# MB9BF12xS register map
File version: 1.0
Registers are 32-bit, read-write, reset 0x0 unless marked. A register's access mark holds for its fields unless they carry their own. Offsets are from the block's base; [hi:lo] are bit positions; {n}, {i} and the like mark numbered series; 'fields as' and 'values as' point back to an identical list.

## CRTRIM — peripheral CRTRIM
Base 0x4002E000
0x00 MCR_PSR 8-bit reset 0x1
  [1:0] CSR
0x04 MCR_FTRM 16-bit reset 0x200
  [9:0] TRD
0x08 MCR_TTRM 8-bit reset 0xF
  [4:0] TRT
0x0C MCR_RLR reset 0x1
  [31:0] TRMLCK

## SWWDT — peripheral SWWDT
Base 0x40012000
0x00 WDOGLOAD reset 0xFFFFFFFF
0x04 WDOGVALUE ro reset 0xFFFFFFFF
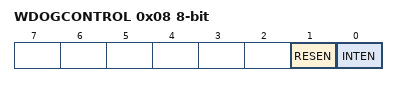
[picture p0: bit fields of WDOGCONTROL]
0x08 WDOGCONTROL 8-bit
  [1] RESEN, [0] INTEN
0x0C WDOGINTCLR reset 0xFFFFFFFF
0x10 WDOGRIS 8-bit ro
  [0] RIS
0xC00 WDOGLOCK

## HWWDT — peripheral HWWDT
Base 0x40011000
0x00 WDG_LDR reset 0xFFFF
0x04 WDG_VLR ro
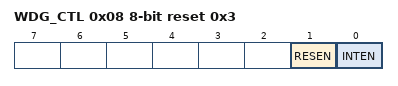
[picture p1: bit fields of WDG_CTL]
0x08 WDG_CTL 8-bit reset 0x3
  [1] RESEN, [0] INTEN
0x0C WDG_ICL 8-bit reset 0xFF (reset mask 0x0)
0x10 WDG_RIS 8-bit ro reset 0xFF (reset mask 0x0)
  [0] RIS
0xC00 WDG_LCK reset 0x1

## DTIM — peripheral DTIM
Base 0x40015000
0x00 TIMER1LOAD (DualTimer1 view)
0x04 TIMER1VALUE ro reset 0xFFFFFFFF
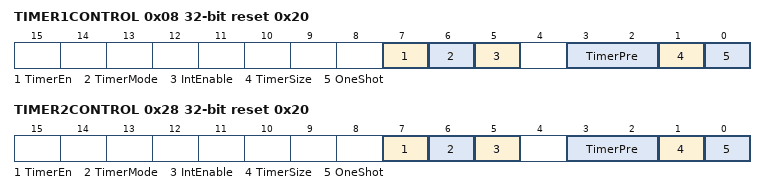
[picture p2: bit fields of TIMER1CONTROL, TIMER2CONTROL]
0x08 TIMER1CONTROL reset 0x20
  [7] TimerEn, [6] TimerMode, [5] IntEnable, [3:2] TimerPre, [1] TimerSize, [0] OneShot
0x0C TIMER1INTCLR wo reset not defined
0x10 TIMER1RIS ro
  [0] TIMER1RIS
0x14 TIMER1MIS ro
  [0] TIMER1MIS
0x18 TIMER1BGLOAD
0x20 TIMER2LOAD
0x24 TIMER2VALUE ro reset 0xFFFFFFFF
0x28 TIMER2CONTROL reset 0x20
  fields as TIMER1CONTROL
0x2C TIMER2INTCLR wo reset not defined
0x30 TIMER2RIS ro
  [0] TIMER1RIS
0x34 TIMER2MIS ro
  [0] TIMER1MIS
0x38 TIMER2BGLOAD

## MFT0 — peripheral MFT0
Base 0x40020000
{0x0+4i} OCU_OCCP{i} 16-bit (i=0..5)
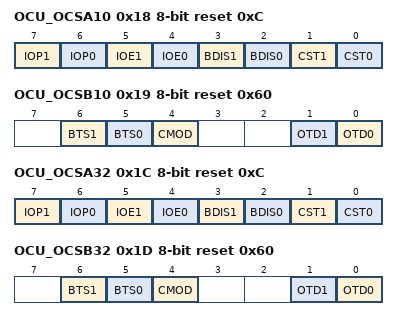
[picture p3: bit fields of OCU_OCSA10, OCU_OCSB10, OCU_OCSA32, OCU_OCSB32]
0x18 OCU_OCSA10 8-bit reset 0xC
  [7] IOP1, [6] IOP0, [5] IOE1, [4] IOE0, [3] BDIS1, [2] BDIS0, [1] CST1, [0] CST0
0x19 OCU_OCSB10 8-bit reset 0x60
  [6] BTS1, [5] BTS0, [4] CMOD, [1] OTD1, [0] OTD0
0x1C OCU_OCSA32 8-bit reset 0xC
  fields as OCU_OCSA10
0x1D OCU_OCSB32 8-bit reset 0x60
  [6] BTS1, [5] BTS0, [4] CMOD, [1] OTD1, [0] OTD0
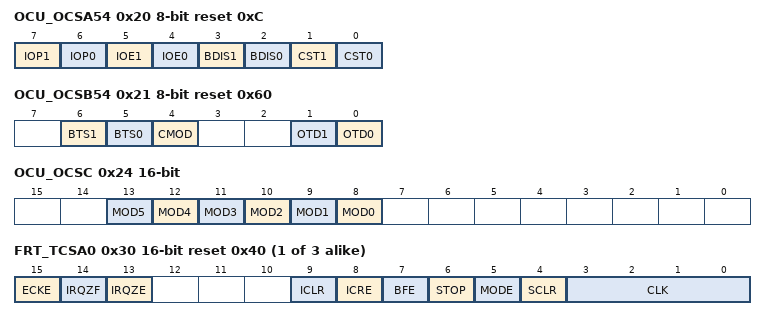
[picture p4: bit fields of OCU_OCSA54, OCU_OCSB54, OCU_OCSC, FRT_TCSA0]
0x20 OCU_OCSA54 8-bit reset 0xC
  fields as OCU_OCSA10
0x21 OCU_OCSB54 8-bit reset 0x60
  [6] BTS1, [5] BTS0, [4] CMOD, [1] OTD1, [0] OTD0
0x24 OCU_OCSC 16-bit
  [n+8] MOD{n} (n=0..5)
{0x28+0x10*i} FRT_TCCP{i} 16-bit reset 0xFFFF (i=0..2)
{0x2C+0x10*i} FRT_TCDT{i} 16-bit (i=0..2)
{0x30+0x10*i} FRT_TCSA{i} 16-bit reset 0x40 (i=0..2)
  [15] ECKE, [14] IRQZF, [13] IRQZE, [9] ICLR, [8] ICRE, [7] BFE, [6] STOP, [5] MODE, [4] SCLR wo, [3:0] CLK
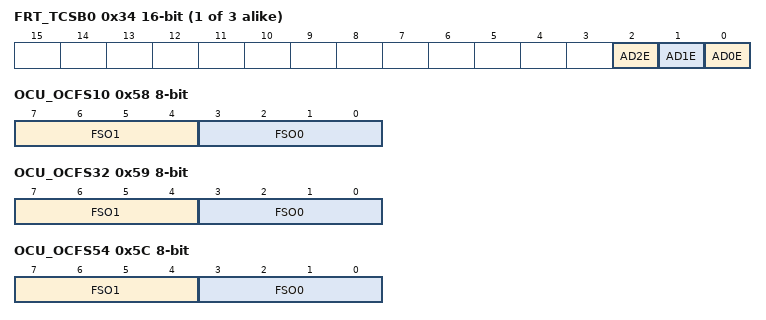
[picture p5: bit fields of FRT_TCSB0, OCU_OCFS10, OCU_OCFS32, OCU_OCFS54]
{0x34+0x10*i} FRT_TCSB{i} 16-bit (i=0..2)
  [2] AD2E, [1] AD1E, [0] AD0E
0x58 OCU_OCFS10 8-bit
  [7:4] FSO1, [3:0] FSO0
0x59 OCU_OCFS32 8-bit
  [7:4] FSO1, [3:0] FSO0
0x5C OCU_OCFS54 8-bit
  [7:4] FSO1, [3:0] FSO0
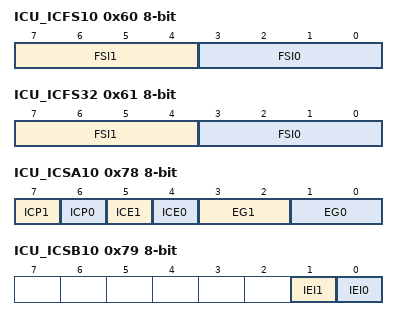
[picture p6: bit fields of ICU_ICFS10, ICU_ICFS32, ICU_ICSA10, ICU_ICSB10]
0x60 ICU_ICFS10 8-bit
  [7:4] FSI1, [3:0] FSI0
0x61 ICU_ICFS32 8-bit
  [7:4] FSI1, [3:0] FSI0
{0x68+4i} ICU_ICCP{i} 16-bit ro reset not defined (i=0..3)
0x78 ICU_ICSA10 8-bit
  [7] ICP1, [6] ICP0, [5] ICE1, [4] ICE0, [3:2] EG1, [1:0] EG0
0x79 ICU_ICSB10 8-bit ro
  [1] IEI1, [0] IEI0
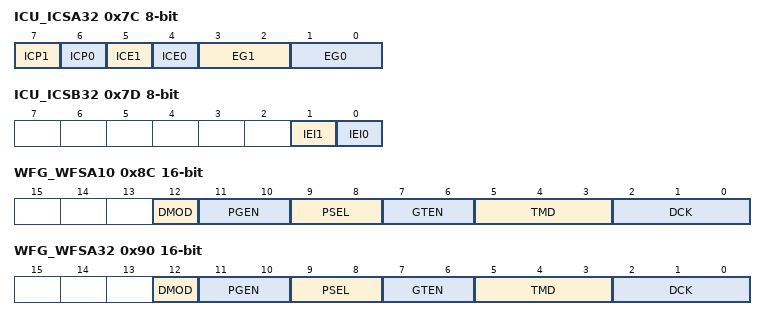
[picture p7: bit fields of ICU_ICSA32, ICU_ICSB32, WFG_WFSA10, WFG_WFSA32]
0x7C ICU_ICSA32 8-bit
  [7] ICP1, [6] ICP0, [5] ICE1, [4] ICE0, [3:2] EG1, [1:0] EG0
0x7D ICU_ICSB32 8-bit ro
  [1] IEI1, [0] IEI0
0x80 WFG_WFTM10 16-bit
0x84 WFG_WFTM32 16-bit
0x88 WFG_WFTM54 16-bit
0x8C WFG_WFSA10 16-bit
  [12] DMOD, [11:10] PGEN, [9:8] PSEL, [7:6] GTEN, [5:3] TMD, [2:0] DCK
0x90 WFG_WFSA32 16-bit
  fields as WFG_WFSA10
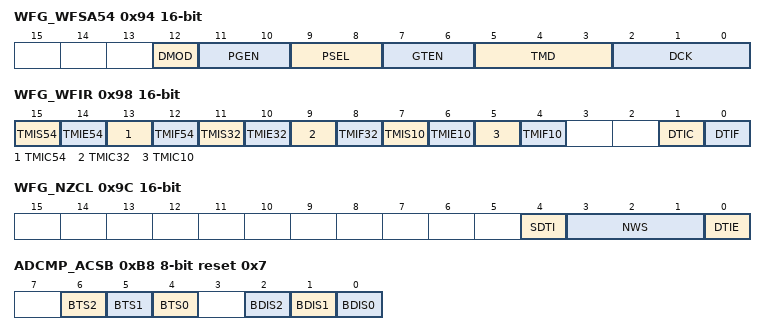
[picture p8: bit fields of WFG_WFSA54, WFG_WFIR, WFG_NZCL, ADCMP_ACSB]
0x94 WFG_WFSA54 16-bit
  fields as WFG_WFSA10
0x98 WFG_WFIR 16-bit
  [15] TMIS54 wo, [14] TMIE54, [13] TMIC54 wo, [12] TMIF54 ro, [11] TMIS32 wo, [10] TMIE32, [9] TMIC32 wo, [8] TMIF32 ro, [7] TMIS10 wo, [6] TMIE10, [5] TMIC10 wo, [4] TMIF10 ro, [1] DTIC wo, [0] DTIF ro
0x9C WFG_NZCL 16-bit
  [4] SDTI wo, [3:1] NWS, [0] DTIE
{0xA0+8i} ADCMP_ACCP{i} 16-bit (i=0..2)
{0xA4+8i} ADCMP_ACCPDN{i} 16-bit (i=0..2)
0xB8 ADCMP_ACSB 8-bit reset 0x7
  [6] BTS2, [5] BTS1, [4] BTS0, [2] BDIS2, [1] BDIS1, [0] BDIS0
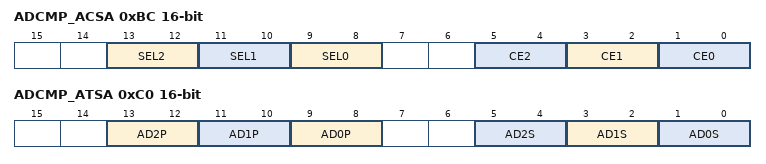
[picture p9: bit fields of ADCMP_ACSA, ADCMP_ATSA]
0xBC ADCMP_ACSA 16-bit
  [13:12] SEL2, [11:10] SEL1, [9:8] SEL0, [5:4] CE2, [3:2] CE1, [1:0] CE0
0xC0 ADCMP_ATSA 16-bit
  [13:12] AD2P, [11:10] AD1P, [9:8] AD0P, [5:4] AD2S, [3:2] AD1S, [1:0] AD0S

## Notices in the file
Licence Terms
FUJITSU SEMICONDUCTOR LIMITED (gLICENSORh) hereby grants and
you (gLICENSEEh) hereby accept a non transferable, non-exclusive
licence to use and copy the deliverables (gDeliverablesh) solely for
the purpose of; (i) developing LICENSEEfs development tools and
distributing such development tools to third parties; (ii) generating
derivative representations of the Deliverables to develop and debug
software for LICENSORfs targeted devices or device series identified
within the Deliverables, (together the gPurposeh) under the following
terms and conditions:
1. Ownership.
The Deliverables are the property of LICENSOR. LICENSEE acquires no
right, title or interest in the Deliverables other than the licence
rights granted herein.
2. Use.
LICENSEE shall only be permitted to use the Deliverables for the
Purpose. LICENSEE shall not reverse engineer, decompile or
disassemble the Deliverables, in whole or in part.
3. Copies.
All copies of the Deliverables must bear the same notice(s) contained
on the original copies of the Deliverables.
4. No Warranty.
THE DELIVERABLES ARE PROVIDED gAS ISh AND ANY EXPRESS, IMPLIED OR
STATUTORY WARRANTIES, INCLUDING, BUT NOT LIMITED TO, THE IMPLIED
WARRANTIES OF MERCHANTABILITY, SATISFACTORY QUALITY AND FITNESS FOR
A PARTICULAR PURPOSE ARE DISCLAIMED.
IN NO EVENT SHALL LICENSOR BE LIABLE FOR ANY DIRECT, INDIRECT,
INCIDENTAL, SPECIAL, EXEMPLARY, OR CONSEQUENTIAL DAMAGES HOWEVER CAUSED
AND ON ANY THEORY OF LIABILITY, WHETHER IN CONTRACT, STRICT LIABILITY,
OR TORT (INCLUDING NEGLIGENCE OR OTHERWISE) ARISING IN ANY WAY OUT OF
THE USE OF THE DELIVERABLES, EVEN IF ADVISED OF THE POSSIBILITY OF SUCH
DAMAGE.
LICENSEE EXPRESSLY ASSUMES ALL LIABILITIES AND RISKS, FOR USE OR
OPERATION OF THE DELIVERABLES.
5.In the event that LICENSEE receives early access to the Deliverables,
LICENSEE acknowledges and agrees that;
(a) notwithstanding the licence grants above, LICENSEE shall only be
permitted to use the Deliverables solely internally for evaluation and
providing feedback to LICENSOR;
(b) except with respect to the limited licence grants in 5(a), LICENSEE
shall be subject to all of the terms and conditions set out above; and
(c) the Deliverables are confidential information and LICENSEE shall
maintain in confidence the Deliverables and apply security measures no
less stringent than the measures that LICENSEE applies to its own like
information, but not less than a reasonable degree of care, to prevent
unauthorised disclosure and use of the Deliverables.
